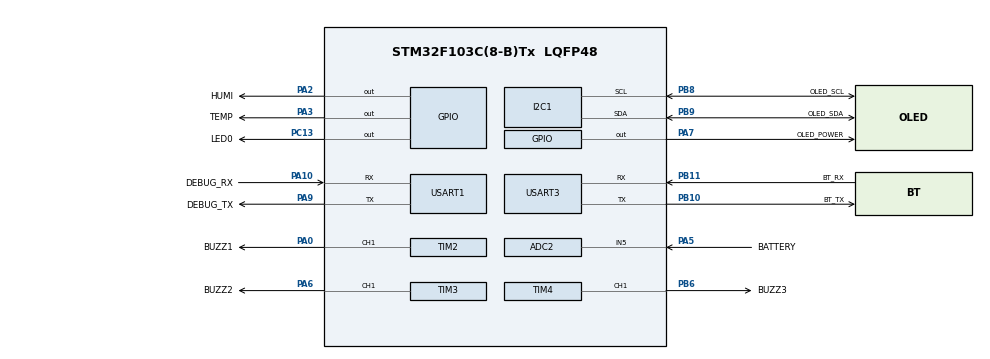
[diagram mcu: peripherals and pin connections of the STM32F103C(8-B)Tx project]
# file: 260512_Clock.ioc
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ADC2.Channel-0\#ChannelRegularConversion=ADC_CHANNEL_5
ADC2.NbrOfConversion=1
ADC2.NbrOfConversionFlag=1
ADC2.Rank-0\#ChannelRegularConversion=1
ADC2.SamplingTime-0\#ChannelRegularConversion=ADC_SAMPLETIME_55CYCLES_5
Dma.I2C1_TX.0.Direction=DMA_MEMORY_TO_PERIPH
Dma.I2C1_TX.0.Instance=DMA1_Channel6
Dma.I2C1_TX.0.MemDataAlignment=DMA_MDATAALIGN_BYTE
Dma.I2C1_TX.0.MemInc=DMA_MINC_ENABLE
Dma.I2C1_TX.0.Mode=DMA_NORMAL
Dma.I2C1_TX.0.PeriphDataAlignment=DMA_PDATAALIGN_BYTE
Dma.I2C1_TX.0.PeriphInc=DMA_PINC_DISABLE
Dma.I2C1_TX.0.Priority=DMA_PRIORITY_MEDIUM
Dma.Request0=I2C1_TX
Dma.Request1=USART1_RX
Dma.Request2=USART1_TX
Dma.Request3=USART3_RX
Dma.Request4=USART3_TX
Dma.USART1_RX.1.Direction=DMA_PERIPH_TO_MEMORY
Dma.USART1_RX.1.Instance=DMA1_Channel5
Dma.USART1_RX.1.MemDataAlignment=DMA_MDATAALIGN_BYTE
Dma.USART1_RX.1.MemInc=DMA_MINC_ENABLE
Dma.USART1_RX.1.Mode=DMA_NORMAL
Dma.USART1_RX.1.PeriphDataAlignment=DMA_PDATAALIGN_BYTE
Dma.USART1_RX.1.PeriphInc=DMA_PINC_DISABLE
Dma.USART1_RX.1.Priority=DMA_PRIORITY_HIGH
Dma.USART1_TX.2.Direction=DMA_MEMORY_TO_PERIPH
Dma.USART1_TX.2.Instance=DMA1_Channel4
Dma.USART1_TX.2.MemDataAlignment=DMA_MDATAALIGN_BYTE
Dma.USART1_TX.2.MemInc=DMA_MINC_ENABLE
Dma.USART1_TX.2.Mode=DMA_NORMAL
Dma.USART1_TX.2.PeriphDataAlignment=DMA_PDATAALIGN_BYTE
Dma.USART1_TX.2.PeriphInc=DMA_PINC_DISABLE
Dma.USART1_TX.2.Priority=DMA_PRIORITY_LOW
Dma.USART3_RX.3.Direction=DMA_PERIPH_TO_MEMORY
Dma.USART3_RX.3.Instance=DMA1_Channel3
Dma.USART3_RX.3.MemDataAlignment=DMA_MDATAALIGN_BYTE
Dma.USART3_RX.3.MemInc=DMA_MINC_ENABLE
Dma.USART3_RX.3.Mode=DMA_NORMAL
Dma.USART3_RX.3.PeriphDataAlignment=DMA_PDATAALIGN_BYTE
Dma.USART3_RX.3.PeriphInc=DMA_PINC_DISABLE
Dma.USART3_RX.3.Priority=DMA_PRIORITY_MEDIUM
Dma.USART3_TX.4.Direction=DMA_MEMORY_TO_PERIPH
Dma.USART3_TX.4.Instance=DMA1_Channel2
Dma.USART3_TX.4.MemDataAlignment=DMA_MDATAALIGN_BYTE
Dma.USART3_TX.4.MemInc=DMA_MINC_ENABLE
Dma.USART3_TX.4.Mode=DMA_NORMAL
Dma.USART3_TX.4.PeriphDataAlignment=DMA_PDATAALIGN_BYTE
Dma.USART3_TX.4.PeriphInc=DMA_PINC_DISABLE
Dma.USART3_TX.4.Priority=DMA_PRIORITY_LOW
I2C1.DutyCycle=I2C_DUTYCYCLE_16_9
I2C1.I2C_Mode=I2C_Fast
Mcu.Family=STM32F1
Mcu.Name=STM32F103C(8-B)Tx
Mcu.Package=LQFP48
NVIC.DMA1_Channel2_IRQn=true\:0\:0\:false\:false\:true\:false\:true\:true
NVIC.DMA1_Channel3_IRQn=true\:0\:0\:false\:false\:true\:false\:true\:true
NVIC.DMA1_Channel4_IRQn=true\:0\:0\:false\:false\:true\:false\:true\:true
NVIC.DMA1_Channel5_IRQn=true\:0\:0\:false\:false\:true\:false\:true\:true
NVIC.DMA1_Channel6_IRQn=true\:0\:0\:false\:false\:true\:false\:true\:true
NVIC.I2C1_ER_IRQn=true\:4\:0\:true\:false\:true\:true\:true\:true
NVIC.I2C1_EV_IRQn=true\:4\:0\:true\:false\:true\:true\:true\:true
NVIC.PriorityGroup=NVIC_PRIORITYGROUP_4
NVIC.RTC_IRQn=true\:10\:0\:true\:false\:true\:true\:true\:true
NVIC.TIM1_UP_IRQn=true\:1\:0\:true\:false\:true\:true\:true\:true
NVIC.USART1_IRQn=true\:5\:0\:true\:false\:true\:false\:true\:true
NVIC.USART3_IRQn=true\:6\:0\:true\:false\:true\:true\:true\:true
PA0-WKUP.GPIO_Label=BUZZ1
PA0-WKUP.Signal=S_TIM2_CH1_ETR
PA10.GPIO_Label=DEBUG_RX
PA10.Mode=Asynchronous
PA10.Signal=USART1_RX
PA13.Mode=Serial_Wire
PA13.Signal=SYS_JTMS-SWDIO
PA14.Mode=Serial_Wire
PA14.Signal=SYS_JTCK-SWCLK
PA2.GPIO_Label=HUMI
PA2.GPIO_ModeDefaultOutputPP=GPIO_MODE_OUTPUT_OD
PA2.GPIO_PuPd=GPIO_PULLUP
PA2.GPIO_Speed=GPIO_SPEED_FREQ_MEDIUM
PA2.PinState=GPIO_PIN_SET
PA2.Signal=GPIO_Output
PA3.GPIO_Label=TEMP
PA3.GPIO_ModeDefaultOutputPP=GPIO_MODE_OUTPUT_OD
PA3.GPIO_PuPd=GPIO_PULLUP
PA3.GPIO_Speed=GPIO_SPEED_FREQ_MEDIUM
PA3.PinState=GPIO_PIN_SET
PA3.Signal=GPIO_Output
PA5.GPIO_Label=BATTERY
PA5.Signal=ADCx_IN5
PA6.GPIO_Label=BUZZ2
PA6.Signal=S_TIM3_CH1
PA7.GPIO_Label=OLED_POWER
PA7.PinState=GPIO_PIN_SET
PA7.Signal=GPIO_Output
PA9.GPIO_Label=DEBUG_TX
PA9.Mode=Asynchronous
PA9.Signal=USART1_TX
PB10.GPIO_Label=BT_TX
PB10.Mode=Asynchronous
PB10.Signal=USART3_TX
PB11.GPIO_Label=BT_RX
PB11.Mode=Asynchronous
PB11.Signal=USART3_RX
PB6.GPIO_Label=BUZZ3
PB6.Signal=S_TIM4_CH1
PB8.GPIO_Label=OLED_SCL
PB8.Mode=I2C
PB8.Signal=I2C1_SCL
PB9.GPIO_Label=OLED_SDA
PB9.Mode=I2C
PB9.Signal=I2C1_SDA
PC13-TAMPER-RTC.GPIO_Label=LED0
PC13-TAMPER-RTC.PinState=GPIO_PIN_SET
PC13-TAMPER-RTC.Signal=GPIO_Output
PD0-OSC_IN.Mode=HSE-External-Oscillator
PD0-OSC_IN.Signal=RCC_OSC_IN
PD1-OSC_OUT.Mode=HSE-External-Oscillator
PD1-OSC_OUT.Signal=RCC_OSC_OUT
ProjectManager.HeapSize=0x200
ProjectManager.StackSize=0x400
ProjectManager.TargetToolchain=CMake
RCC.ADCPresc=RCC_ADCPCLK2_DIV6
RCC.AHBFreq_Value=72000000
RCC.APB1CLKDivider=RCC_HCLK_DIV2
RCC.APB1Freq_Value=36000000
RCC.APB1TimFreq_Value=72000000
RCC.APB2Freq_Value=72000000
RCC.APB2TimFreq_Value=72000000
RCC.HCLKFreq_Value=72000000
RCC.PLLMUL=RCC_PLL_MUL9
RCC.PLLSourceVirtual=RCC_PLLSOURCE_HSE
RCC.RTCClockSelection=RCC_RTCCLKSOURCE_HSE_DIV128
RCC.SYSCLKFreq_VALUE=72000000
RCC.SYSCLKSource=RCC_SYSCLKSOURCE_PLLCLK
RCC.USBFreq_Value=72000000
RTC.AsynchPrediv=62500
RTC.AutoPrediv=0
RTC.Format=RTC_FORMAT_BIN
SH.ADCx_IN5.0=ADC2_IN5,IN5
SH.S_TIM2_CH1_ETR.0=TIM2_CH1,Output Compare1 CH1
SH.S_TIM3_CH1.0=TIM3_CH1,Output Compare1 CH1
SH.S_TIM4_CH1.0=TIM4_CH1,Output Compare1 CH1
TIM1.Period=6249
TIM1.Prescaler=71
TIM2.AutoReloadPreload=TIM_AUTORELOAD_PRELOAD_ENABLE
TIM2.Channel-Output\ Compare1\ CH1=TIM_CHANNEL_1
TIM2.OCMode_1=TIM_OCMODE_FORCED_ACTIVE
TIM2.Prescaler=2
TIM3.AutoReloadPreload=TIM_AUTORELOAD_PRELOAD_ENABLE
TIM3.Channel-Output\ Compare1\ CH1=TIM_CHANNEL_1
TIM3.OCMode_1=TIM_OCMODE_FORCED_ACTIVE
TIM3.Prescaler=2
TIM4.AutoReloadPreload=TIM_AUTORELOAD_PRELOAD_ENABLE
TIM4.Channel-Output\ Compare1\ CH1=TIM_CHANNEL_1
TIM4.OCMode_1=TIM_OCMODE_FORCED_ACTIVE
TIM4.Prescaler=2
USART1.VirtualMode=VM_ASYNC
USART3.VirtualMode=VM_ASYNC
VP_RTC_VS_RTC_Activate.Mode=RTC_Enabled
VP_TIM1_VS_ClockSourceINT.Mode=Internal
VP_TIM2_VS_ClockSourceINT.Mode=Internal
VP_TIM3_VS_ClockSourceINT.Mode=Internal
VP_TIM4_VS_ClockSourceINT.Mode=Internal
board=custom

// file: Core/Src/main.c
/* USER CODE BEGIN Header */
/**
  ******************************************************************************
  * @file           : main.c
  * @brief          : Main program body
  ******************************************************************************
  * @attention
  *
  * Copyright (c) 2026 STMicroelectronics.
  * All rights reserved.
  *
  * This software is licensed under terms that can be found in the LICENSE file
  * in the root directory of this software component.
  * If no LICENSE file comes with this software, it is provided AS-IS.
  *
  ******************************************************************************
  */
/* USER CODE END Header */
#include "main.h"
#include "adc.h"
#include "dma.h"
#include "i2c.h"
#include "rtc.h"
#include "tim.h"
#include "usart.h"
#include "gpio.h"

/* USER CODE BEGIN Includes */
#include "system.h"
#include "temp.h"
#include "dht11.h"
#include "t_h_stat.h"
#include "msg_parse.h"
/* USER CODE END Includes */

void SystemClock_Config(void);

int main(void)
{

  /* MCU Configuration--------------------------------------------------------*/

  /* Reset of all peripherals, Initializes the Flash interface and the Systick. */
  LL_APB2_GRP1_EnableClock(LL_APB2_GRP1_PERIPH_AFIO);
  LL_APB1_GRP1_EnableClock(LL_APB1_GRP1_PERIPH_PWR);

  /* System interrupt init*/
  NVIC_SetPriorityGrouping(NVIC_PRIORITYGROUP_4);

  /** NOJTAG: JTAG-DP Disabled and SW-DP Enabled
  */
  LL_GPIO_AF_Remap_SWJ_NOJTAG();

  /* Configure the system clock */
  SystemClock_Config();

  /* Initialize all configured peripherals */
  MX_GPIO_Init();
  MX_DMA_Init();
  MX_I2C1_Init();
  MX_USART1_UART_Init();
  MX_USART3_UART_Init();
  MX_TIM2_Init();
  MX_TIM3_Init();
  MX_TIM4_Init();
  MX_TIM1_Init();
  MX_RTC_Init();
  MX_ADC2_Init();
  /* USER CODE BEGIN 2 */

  sys_init();

  /* USER CODE END 2 */

  /* Infinite loop */
  /* USER CODE BEGIN WHILE */
  while (1)
  {
    sys_task();
    temp_task();
    dht11_task();
    send_help_task();
    t_h_stat_show_task();
    /* USER CODE END WHILE */

  }
}

void SystemClock_Config(void)
{
  LL_FLASH_SetLatency(LL_FLASH_LATENCY_2);
  while(LL_FLASH_GetLatency()!= LL_FLASH_LATENCY_2)
  {
  }
  LL_RCC_HSE_Enable();

   /* Wait till HSE is ready */
  while(LL_RCC_HSE_IsReady() != 1)
  {

  }
  LL_PWR_EnableBkUpAccess();
  if(LL_RCC_GetRTCClockSource() != LL_RCC_RTC_CLKSOURCE_HSE_DIV128)
  {
    LL_RCC_ForceBackupDomainReset();
    LL_RCC_ReleaseBackupDomainReset();
    LL_RCC_SetRTCClockSource(LL_RCC_RTC_CLKSOURCE_HSE_DIV128);
  }
  LL_RCC_EnableRTC();
  LL_RCC_PLL_ConfigDomain_SYS(LL_RCC_PLLSOURCE_HSE_DIV_1, LL_RCC_PLL_MUL_9);
  LL_RCC_PLL_Enable();

   /* Wait till PLL is ready */
  while(LL_RCC_PLL_IsReady() != 1)
  {

  }
  LL_RCC_SetAHBPrescaler(LL_RCC_SYSCLK_DIV_1);
  LL_RCC_SetAPB1Prescaler(LL_RCC_APB1_DIV_2);
  LL_RCC_SetAPB2Prescaler(LL_RCC_APB2_DIV_1);
  LL_RCC_SetSysClkSource(LL_RCC_SYS_CLKSOURCE_PLL);

   /* Wait till System clock is ready */
  while(LL_RCC_GetSysClkSource() != LL_RCC_SYS_CLKSOURCE_STATUS_PLL)
  {

  }
  LL_Init1msTick(72000000);
  LL_SetSystemCoreClock(72000000);
  LL_RCC_SetADCClockSource(LL_RCC_ADC_CLKSRC_PCLK2_DIV_6);
}

void Error_Handler(void)
{
  __disable_irq();
  while (1)
  {
  }
}
